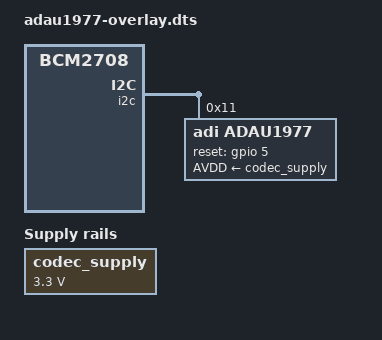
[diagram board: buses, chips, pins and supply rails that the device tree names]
/dts-v1/;
/plugin/;

/ {
	compatible = "brcm,bcm2708";
    
	fragment@0 {
		target = <&soc>;
		
		__overlay__ {
			codec_supply: fixedregulator@0 {
				compatible = "regulator-fixed";
				regulator-name = "AVDD";
				regulator-min-microvolt = <3300000>;
				regulator-max-microvolt = <3300000>;
			};
		};
	};

	fragment@1 {
        	target = <&i2c>;
        	
		__overlay__ {
			adau1977: codec@11 {
                        	compatible = "adi,adau1977";
                        	reg = <0x11>;
                        	reset-gpios = <&gpio 5 0>;
                        	AVDD-supply = <&codec_supply>;
                	};
        	};
	};
};    
